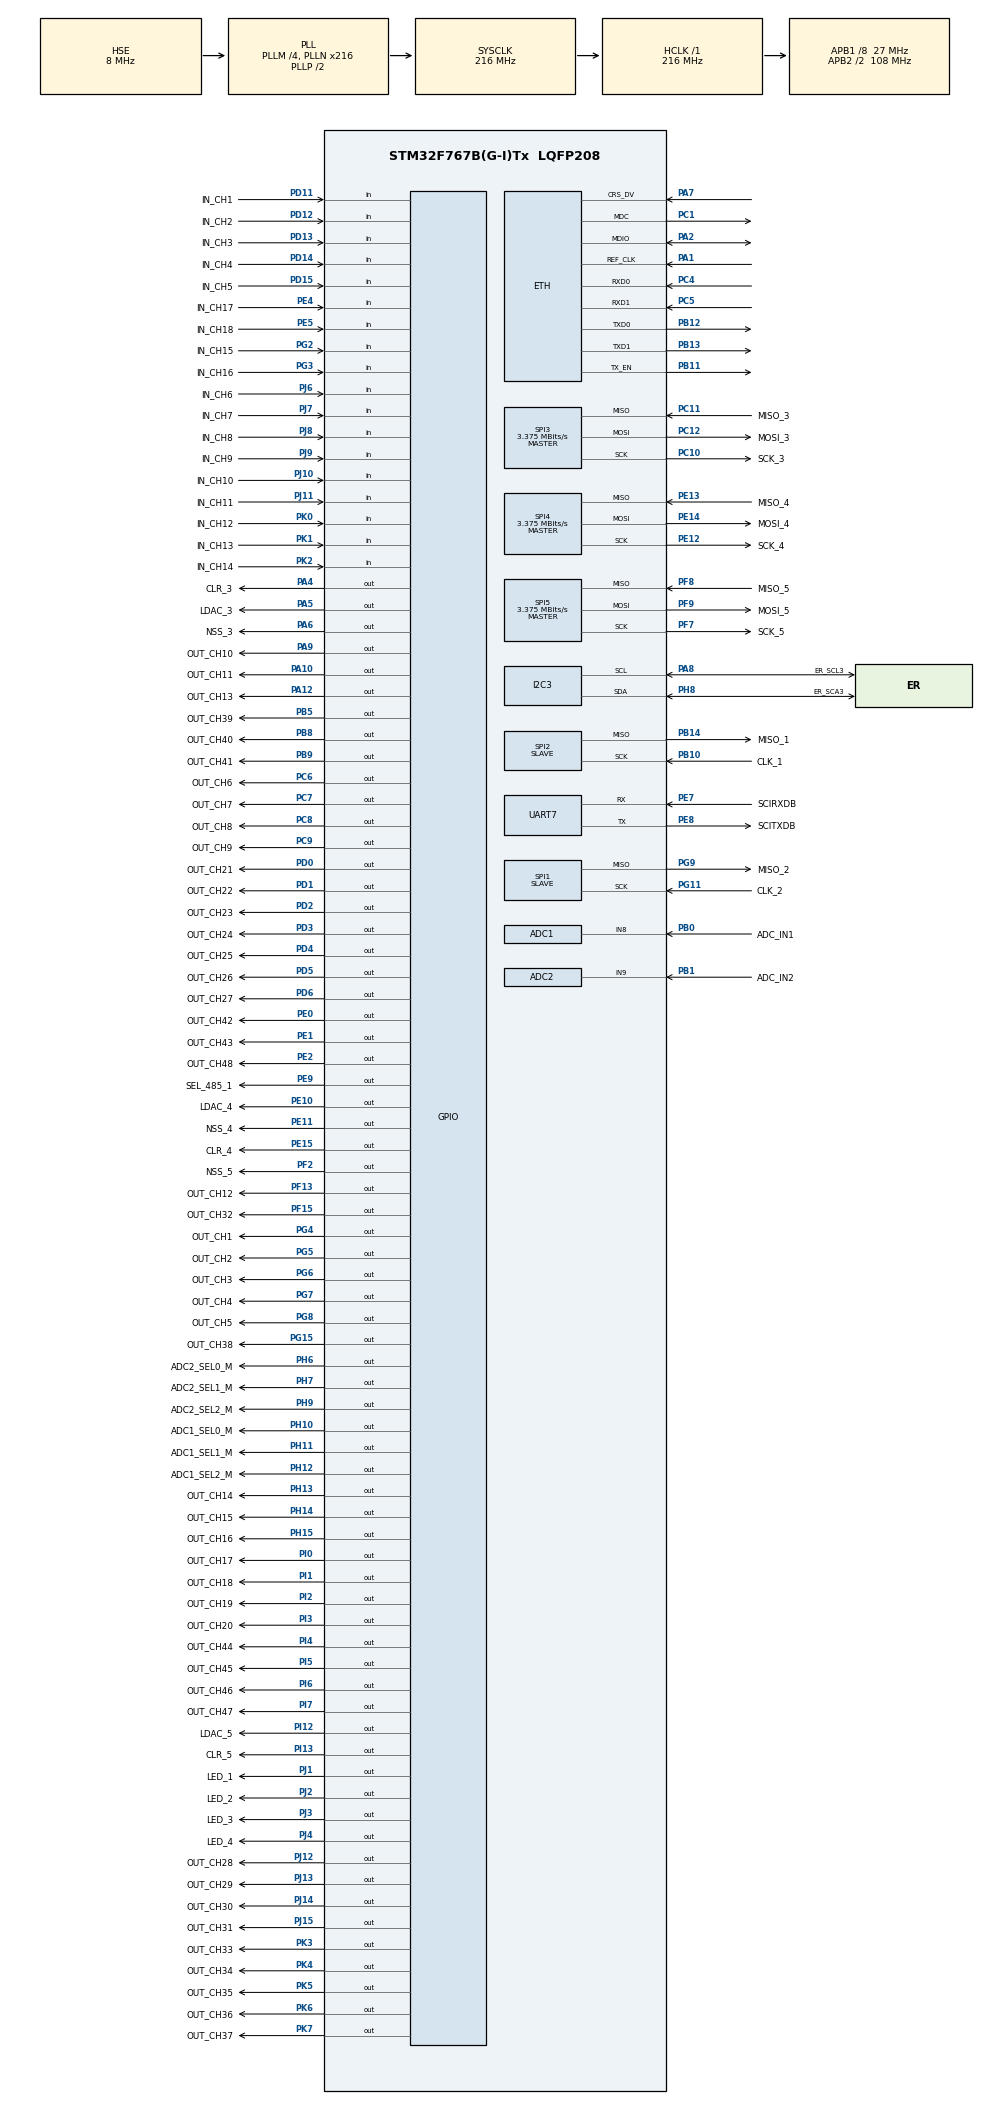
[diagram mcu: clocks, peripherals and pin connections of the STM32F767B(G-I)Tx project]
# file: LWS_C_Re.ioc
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ADC1.Channel-0\#ChannelRegularConversion=ADC_CHANNEL_8
ADC1.ClockPrescaler=ADC_CLOCK_SYNC_PCLK_DIV6
ADC1.EOCSelection=ADC_EOC_SEQ_CONV
ADC1.NbrOfConversionFlag=1
ADC1.Rank-0\#ChannelRegularConversion=1
ADC1.SamplingTime-0\#ChannelRegularConversion=ADC_SAMPLETIME_84CYCLES
ADC1.master=1
ADC2.Channel-0\#ChannelRegularConversion=ADC_CHANNEL_9
ADC2.ClockPrescaler=ADC_CLOCK_SYNC_PCLK_DIV6
ADC2.ContinuousConvMode=DISABLE
ADC2.DMAContinuousRequests=DISABLE
ADC2.EOCSelection=ADC_EOC_SEQ_CONV
ADC2.NbrOfConversion=1
ADC2.NbrOfConversionFlag=1
ADC2.Rank-0\#ChannelRegularConversion=1
ADC2.SamplingTime-0\#ChannelRegularConversion=ADC_SAMPLETIME_84CYCLES
ADC2.ScanConvMode=ADC_SCAN_DISABLE
CORTEX_M7.CPU_DCache=Disabled
CORTEX_M7.CPU_ICache=Disabled
Dma.Request0=UART7_TX
Dma.Request1=SPI1_TX
Dma.Request2=SPI2_TX
Dma.SPI1_TX.1.Direction=DMA_MEMORY_TO_PERIPH
Dma.SPI1_TX.1.FIFOMode=DMA_FIFOMODE_DISABLE
Dma.SPI1_TX.1.Instance=DMA2_Stream3
Dma.SPI1_TX.1.MemDataAlignment=DMA_MDATAALIGN_HALFWORD
Dma.SPI1_TX.1.MemInc=DMA_MINC_ENABLE
Dma.SPI1_TX.1.Mode=DMA_CIRCULAR
Dma.SPI1_TX.1.PeriphDataAlignment=DMA_PDATAALIGN_HALFWORD
Dma.SPI1_TX.1.PeriphInc=DMA_PINC_DISABLE
Dma.SPI1_TX.1.Priority=DMA_PRIORITY_LOW
Dma.SPI2_TX.2.Direction=DMA_MEMORY_TO_PERIPH
Dma.SPI2_TX.2.FIFOMode=DMA_FIFOMODE_DISABLE
Dma.SPI2_TX.2.Instance=DMA1_Stream4
Dma.SPI2_TX.2.MemDataAlignment=DMA_MDATAALIGN_HALFWORD
Dma.SPI2_TX.2.MemInc=DMA_MINC_ENABLE
Dma.SPI2_TX.2.Mode=DMA_CIRCULAR
Dma.SPI2_TX.2.PeriphDataAlignment=DMA_PDATAALIGN_HALFWORD
Dma.SPI2_TX.2.PeriphInc=DMA_PINC_DISABLE
Dma.SPI2_TX.2.Priority=DMA_PRIORITY_LOW
Dma.UART7_TX.0.Direction=DMA_MEMORY_TO_PERIPH
Dma.UART7_TX.0.FIFOMode=DMA_FIFOMODE_DISABLE
Dma.UART7_TX.0.Instance=DMA1_Stream1
Dma.UART7_TX.0.MemDataAlignment=DMA_MDATAALIGN_BYTE
Dma.UART7_TX.0.MemInc=DMA_MINC_ENABLE
Dma.UART7_TX.0.Mode=DMA_NORMAL
Dma.UART7_TX.0.PeriphDataAlignment=DMA_PDATAALIGN_BYTE
Dma.UART7_TX.0.PeriphInc=DMA_PINC_DISABLE
Dma.UART7_TX.0.Priority=DMA_PRIORITY_VERY_HIGH
ETH.MediaInterface=HAL_ETH_RMII_MODE
I2C3.Timing=0x00606A9B
LWIP.BSP.number=1
LWIP.GATEWAY_ADDRESS=192.168.000.001
LWIP.IP_ADDRESS=192.168.000.225
LWIP.LWIP_DHCP=0
LWIP.NETMASK_ADDRESS=255.255.255.000
LWIP.Version=v2.1.2_Cube
LWIP0.BSP.STBoard=false
LWIP0.BSP.api=BSP_COMPONENT_DRIVER
LWIP0.BSP.component=LAN8742
LWIP0.BSP.instance=LAN8742
LWIP0.BSP.name=Driver_PHY
LWIP0.BSP.semaphore=S_LAN8742
LWIP0.BSP.solution=LAN8742
Mcu.Family=STM32F7
Mcu.Name=STM32F767B(G-I)Tx
Mcu.Package=LQFP208
NVIC.DMA1_Stream1_IRQn=true\:0\:0\:false\:false\:true\:false\:true\:true
NVIC.DMA1_Stream4_IRQn=true\:0\:0\:false\:false\:true\:false\:true\:true
NVIC.DMA2_Stream3_IRQn=true\:0\:0\:false\:false\:true\:false\:true\:true
NVIC.ETH_IRQn=true\:0\:0\:false\:false\:true\:true\:true\:true
NVIC.ETH_WKUP_IRQn=true\:0\:0\:false\:false\:true\:true\:true\:true
NVIC.PriorityGroup=NVIC_PRIORITYGROUP_4
NVIC.SPI1_IRQn=true\:0\:0\:false\:false\:true\:true\:true\:true
NVIC.SPI2_IRQn=true\:0\:0\:false\:false\:true\:true\:true\:true
NVIC.TIM2_IRQn=true\:0\:0\:false\:false\:true\:true\:true\:true
NVIC.TIM4_IRQn=true\:0\:0\:false\:false\:true\:true\:true\:true
NVIC.TIM5_IRQn=true\:0\:0\:false\:false\:true\:true\:true\:true
NVIC.TIM6_DAC_IRQn=true\:15\:0\:false\:false\:true\:false\:true\:true
NVIC.TIM7_IRQn=true\:0\:0\:false\:false\:true\:true\:true\:true
NVIC.TimeBase=TIM6_DAC_IRQn
NVIC.TimeBaseIP=TIM6
NVIC.UART7_IRQn=true\:0\:0\:false\:false\:true\:true\:true\:true
PA1.Mode=RMII
PA1.Signal=ETH_REF_CLK
PA10.GPIO_Label=OUT_CH11
PA10.PinState=GPIO_PIN_SET
PA10.Signal=GPIO_Output
PA12.GPIO_Label=OUT_CH13
PA12.PinState=GPIO_PIN_SET
PA12.Signal=GPIO_Output
PA13.Mode=JTAG_5_pins
PA13.Signal=SYS_JTMS-SWDIO
PA14.Mode=JTAG_5_pins
PA14.Signal=SYS_JTCK-SWCLK
PA15.Mode=JTAG_5_pins
PA15.Signal=SYS_JTDI
PA2.Mode=RMII
PA2.Signal=ETH_MDIO
PA4.GPIO_Label=CLR_3
PA4.Signal=GPIO_Output
PA5.GPIO_Label=LDAC_3
PA5.Signal=GPIO_Output
PA6.GPIO_Label=NSS_3
PA6.Signal=GPIO_Output
PA7.Mode=RMII
PA7.Signal=ETH_CRS_DV
PA8.GPIO_Label=ER_SCL3
PA8.Mode=I2C
PA8.Signal=I2C3_SCL
PA9.GPIO_Label=OUT_CH10
PA9.PinState=GPIO_PIN_SET
PA9.Signal=GPIO_Output
PB0.GPIO_Label=ADC_IN1
PB0.Signal=ADCx_IN8
PB1.GPIO_Label=ADC_IN2
PB1.Signal=ADCx_IN9
PB10.GPIO_Label=CLK_1
PB10.Mode=TX_Only_Simplex_Unidirect_Slave
PB10.Signal=SPI2_SCK
PB11.Mode=RMII
PB11.Signal=ETH_TX_EN
PB12.Mode=RMII
PB12.Signal=ETH_TXD0
PB13.Mode=RMII
PB13.Signal=ETH_TXD1
PB14.GPIO_Label=MISO_1
PB14.Mode=TX_Only_Simplex_Unidirect_Slave
PB14.Signal=SPI2_MISO
PB3.Mode=JTAG_5_pins
PB3.Signal=SYS_JTDO-SWO
PB4.Mode=JTAG_5_pins
PB4.Signal=SYS_JTRST
PB5.GPIO_Label=OUT_CH39
PB5.PinState=GPIO_PIN_SET
PB5.Signal=GPIO_Output
PB8.GPIO_Label=OUT_CH40
PB8.PinState=GPIO_PIN_SET
PB8.Signal=GPIO_Output
PB9.GPIO_Label=OUT_CH41
PB9.PinState=GPIO_PIN_SET
PB9.Signal=GPIO_Output
PC1.Mode=RMII
PC1.Signal=ETH_MDC
PC10.GPIO_Label=SCK_3
PC10.Mode=Full_Duplex_Master
PC10.Signal=SPI3_SCK
PC11.GPIO_Label=MISO_3
PC11.Mode=Full_Duplex_Master
PC11.Signal=SPI3_MISO
PC12.GPIO_Label=MOSI_3
PC12.Mode=Full_Duplex_Master
PC12.Signal=SPI3_MOSI
PC14/OSC32_IN.Mode=LSE-External-Oscillator
PC14/OSC32_IN.Signal=RCC_OSC32_IN
PC15/OSC32_OUT.Mode=LSE-External-Oscillator
PC15/OSC32_OUT.Signal=RCC_OSC32_OUT
PC4.Mode=RMII
PC4.Signal=ETH_RXD0
PC5.Mode=RMII
PC5.Signal=ETH_RXD1
PC6.GPIO_Label=OUT_CH6
PC6.PinState=GPIO_PIN_SET
PC6.Signal=GPIO_Output
PC7.GPIO_Label=OUT_CH7
PC7.PinState=GPIO_PIN_SET
PC7.Signal=GPIO_Output
PC8.GPIO_Label=OUT_CH8
PC8.PinState=GPIO_PIN_SET
PC8.Signal=GPIO_Output
PC9.GPIO_Label=OUT_CH9
PC9.PinState=GPIO_PIN_SET
PC9.Signal=GPIO_Output
PD0.GPIO_Label=OUT_CH21
PD0.PinState=GPIO_PIN_SET
PD0.Signal=GPIO_Output
PD1.GPIO_Label=OUT_CH22
PD1.PinState=GPIO_PIN_SET
PD1.Signal=GPIO_Output
PD11.GPIO_Label=IN_CH1
PD11.Signal=GPIO_Input
PD12.GPIO_Label=IN_CH2
PD12.Signal=GPIO_Input
PD13.GPIO_Label=IN_CH3
PD13.Signal=GPIO_Input
PD14.GPIO_Label=IN_CH4
PD14.Signal=GPIO_Input
PD15.GPIO_Label=IN_CH5
PD15.Signal=GPIO_Input
PD2.GPIO_Label=OUT_CH23
PD2.PinState=GPIO_PIN_SET
PD2.Signal=GPIO_Output
PD3.GPIO_Label=OUT_CH24
PD3.PinState=GPIO_PIN_SET
PD3.Signal=GPIO_Output
PD4.GPIO_Label=OUT_CH25
PD4.PinState=GPIO_PIN_SET
PD4.Signal=GPIO_Output
PD5.GPIO_Label=OUT_CH26
PD5.PinState=GPIO_PIN_SET
PD5.Signal=GPIO_Output
PD6.GPIO_Label=OUT_CH27
PD6.PinState=GPIO_PIN_SET
PD6.Signal=GPIO_Output
PE0.GPIO_Label=OUT_CH42
PE0.PinState=GPIO_PIN_SET
PE0.Signal=GPIO_Output
PE1.GPIO_Label=OUT_CH43
PE1.PinState=GPIO_PIN_SET
PE1.Signal=GPIO_Output
PE10.GPIO_Label=LDAC_4
PE10.Signal=GPIO_Output
PE11.GPIO_Label=NSS_4
PE11.Signal=GPIO_Output
PE12.GPIO_Label=SCK_4
PE12.Mode=Full_Duplex_Master
PE12.Signal=SPI4_SCK
PE13.GPIO_Label=MISO_4
PE13.Mode=Full_Duplex_Master
PE13.Signal=SPI4_MISO
PE14.GPIO_Label=MOSI_4
PE14.Mode=Full_Duplex_Master
PE14.Signal=SPI4_MOSI
PE15.GPIO_Label=CLR_4
PE15.Signal=GPIO_Output
PE2.GPIO_Label=OUT_CH48
PE2.PinState=GPIO_PIN_SET
PE2.Signal=GPIO_Output
PE4.GPIO_Label=IN_CH17
PE4.Signal=GPIO_Input
PE5.GPIO_Label=IN_CH18
PE5.Signal=GPIO_Input
PE7.GPIO_Label=SCIRXDB
PE7.Mode=Asynchronous
PE7.Signal=UART7_RX
PE8.GPIO_Label=SCITXDB
PE8.Mode=Asynchronous
PE8.Signal=UART7_TX
PE9.GPIO_Label=SEL_485_1
PE9.Signal=GPIO_Output
PF13.GPIO_Label=OUT_CH12
PF13.PinState=GPIO_PIN_SET
PF13.Signal=GPIO_Output
PF15.GPIO_Label=OUT_CH32
PF15.PinState=GPIO_PIN_SET
PF15.Signal=GPIO_Output
PF2.GPIO_Label=NSS_5
PF2.Signal=GPIO_Output
PF7.GPIO_Label=SCK_5
PF7.Mode=Full_Duplex_Master
PF7.Signal=SPI5_SCK
PF8.GPIO_Label=MISO_5
PF8.Mode=Full_Duplex_Master
PF8.Signal=SPI5_MISO
PF9.GPIO_Label=MOSI_5
PF9.Mode=Full_Duplex_Master
PF9.Signal=SPI5_MOSI
PG11.GPIO_Label=CLK_2
PG11.Mode=TX_Only_Simplex_Unidirect_Slave
PG11.Signal=SPI1_SCK
PG15.GPIO_Label=OUT_CH38
PG15.PinState=GPIO_PIN_SET
PG15.Signal=GPIO_Output
PG2.GPIO_Label=IN_CH15
PG2.Signal=GPIO_Input
PG3.GPIO_Label=IN_CH16
PG3.Signal=GPIO_Input
PG4.GPIO_Label=OUT_CH1
PG4.PinState=GPIO_PIN_SET
PG4.Signal=GPIO_Output
PG5.GPIO_Label=OUT_CH2
PG5.PinState=GPIO_PIN_SET
PG5.Signal=GPIO_Output
PG6.GPIO_Label=OUT_CH3
PG6.PinState=GPIO_PIN_SET
PG6.Signal=GPIO_Output
PG7.GPIO_Label=OUT_CH4
PG7.PinState=GPIO_PIN_SET
PG7.Signal=GPIO_Output
PG8.GPIO_Label=OUT_CH5
PG8.PinState=GPIO_PIN_SET
PG8.Signal=GPIO_Output
PG9.GPIO_Label=MISO_2
PG9.Mode=TX_Only_Simplex_Unidirect_Slave
PG9.Signal=SPI1_MISO
PH0/OSC_IN.Mode=HSE-External-Oscillator
PH0/OSC_IN.Signal=RCC_OSC_IN
PH1/OSC_OUT.Mode=HSE-External-Oscillator
PH1/OSC_OUT.Signal=RCC_OSC_OUT
PH10.GPIO_Label=ADC1_SEL0_M
PH10.Signal=GPIO_Output
PH11.GPIO_Label=ADC1_SEL1_M
PH11.Signal=GPIO_Output
PH12.GPIO_Label=ADC1_SEL2_M
PH12.Signal=GPIO_Output
PH13.GPIO_Label=OUT_CH14
PH13.PinState=GPIO_PIN_SET
PH13.Signal=GPIO_Output
PH14.GPIO_Label=OUT_CH15
PH14.PinState=GPIO_PIN_SET
PH14.Signal=GPIO_Output
PH15.GPIO_Label=OUT_CH16
PH15.PinState=GPIO_PIN_SET
PH15.Signal=GPIO_Output
PH6.GPIO_Label=ADC2_SEL0_M
PH6.Signal=GPIO_Output
PH7.GPIO_Label=ADC2_SEL1_M
PH7.Signal=GPIO_Output
PH8.GPIO_Label=ER_SCA3
PH8.Mode=I2C
PH8.Signal=I2C3_SDA
PH9.GPIO_Label=ADC2_SEL2_M
PH9.Signal=GPIO_Output
PI0.GPIO_Label=OUT_CH17
PI0.PinState=GPIO_PIN_SET
PI0.Signal=GPIO_Output
PI1.GPIO_Label=OUT_CH18
PI1.PinState=GPIO_PIN_SET
PI1.Signal=GPIO_Output
PI12.GPIO_Label=LDAC_5
PI12.Signal=GPIO_Output
PI13.GPIO_Label=CLR_5
PI13.Signal=GPIO_Output
PI2.GPIO_Label=OUT_CH19
PI2.PinState=GPIO_PIN_SET
PI2.Signal=GPIO_Output
PI3.GPIO_Label=OUT_CH20
PI3.PinState=GPIO_PIN_SET
PI3.Signal=GPIO_Output
PI4.GPIO_Label=OUT_CH44
PI4.PinState=GPIO_PIN_SET
PI4.Signal=GPIO_Output
PI5.GPIO_Label=OUT_CH45
PI5.PinState=GPIO_PIN_SET
PI5.Signal=GPIO_Output
PI6.GPIO_Label=OUT_CH46
PI6.PinState=GPIO_PIN_SET
PI6.Signal=GPIO_Output
PI7.GPIO_Label=OUT_CH47
PI7.PinState=GPIO_PIN_SET
PI7.Signal=GPIO_Output
PJ1.GPIO_Label=LED_1
PJ1.Signal=GPIO_Output
PJ10.GPIO_Label=IN_CH10
PJ10.Signal=GPIO_Input
PJ11.GPIO_Label=IN_CH11
PJ11.Signal=GPIO_Input
PJ12.GPIO_Label=OUT_CH28
PJ12.PinState=GPIO_PIN_SET
PJ12.Signal=GPIO_Output
PJ13.GPIO_Label=OUT_CH29
PJ13.PinState=GPIO_PIN_SET
PJ13.Signal=GPIO_Output
PJ14.GPIO_Label=OUT_CH30
PJ14.PinState=GPIO_PIN_SET
PJ14.Signal=GPIO_Output
PJ15.GPIO_Label=OUT_CH31
PJ15.PinState=GPIO_PIN_SET
PJ15.Signal=GPIO_Output
PJ2.GPIO_Label=LED_2
PJ2.Signal=GPIO_Output
PJ3.GPIO_Label=LED_3
PJ3.Signal=GPIO_Output
PJ4.GPIO_Label=LED_4
PJ4.Signal=GPIO_Output
PJ6.GPIO_Label=IN_CH6
PJ6.Signal=GPIO_Input
PJ7.GPIO_Label=IN_CH7
PJ7.Signal=GPIO_Input
PJ8.GPIO_Label=IN_CH8
PJ8.Signal=GPIO_Input
PJ9.GPIO_Label=IN_CH9
PJ9.Signal=GPIO_Input
PK0.GPIO_Label=IN_CH12
PK0.Signal=GPIO_Input
PK1.GPIO_Label=IN_CH13
PK1.Signal=GPIO_Input
PK2.GPIO_Label=IN_CH14
PK2.Signal=GPIO_Input
PK3.GPIO_Label=OUT_CH33
PK3.PinState=GPIO_PIN_SET
PK3.Signal=GPIO_Output
PK4.GPIO_Label=OUT_CH34
PK4.PinState=GPIO_PIN_SET
PK4.Signal=GPIO_Output
PK5.GPIO_Label=OUT_CH35
PK5.PinState=GPIO_PIN_SET
PK5.Signal=GPIO_Output
PK6.GPIO_Label=OUT_CH36
PK6.PinState=GPIO_PIN_SET
PK6.Signal=GPIO_Output
PK7.GPIO_Label=OUT_CH37
PK7.PinState=GPIO_PIN_SET
PK7.Signal=GPIO_Output
ProjectManager.HeapSize=0x2000
ProjectManager.StackSize=0x4000
ProjectManager.TargetToolchain=STM32CubeIDE
RCC.AHBFreq_Value=216000000
RCC.APB1CLKDivider=RCC_HCLK_DIV8
RCC.APB1Freq_Value=27000000
RCC.APB1TimFreq_Value=54000000
RCC.APB2CLKDivider=RCC_HCLK_DIV2
RCC.APB2Freq_Value=108000000
RCC.APB2TimFreq_Value=216000000
RCC.CortexFreq_Value=216000000
RCC.HCLKFreq_Value=216000000
RCC.HSE_VALUE=8000000
RCC.HSI_VALUE=16000000
RCC.PLLM=4
RCC.PLLN=216
RCC.PLLSourceVirtual=RCC_PLLSOURCE_HSE
RCC.SYSCLKFreq_VALUE=216000000
RCC.SYSCLKSource=RCC_SYSCLKSOURCE_PLLCLK
RCC.USBFreq_Value=216000000
RCC.VCOOutputFreq_Value=432000000
SH.ADCx_IN8.0=ADC1_IN8,IN8
SH.ADCx_IN9.0=ADC2_IN9,IN9
SPI1.CLKPhase=SPI_PHASE_1EDGE
SPI1.CLKPolarity=SPI_POLARITY_LOW
SPI1.CRCCalculation=SPI_CRCCALCULATION_DISABLE
SPI1.DataSize=SPI_DATASIZE_16BIT
SPI1.Direction=SPI_DIRECTION_2LINES
SPI1.Mode=SPI_MODE_SLAVE
SPI1.TIMode=SPI_TIMODE_DISABLE
SPI1.VirtualType=VM_SLAVE
SPI2.CLKPhase=SPI_PHASE_1EDGE
SPI2.CLKPolarity=SPI_POLARITY_LOW
SPI2.DataSize=SPI_DATASIZE_16BIT
SPI2.Direction=SPI_DIRECTION_2LINES
SPI2.FirstBit=SPI_FIRSTBIT_MSB
SPI2.Mode=SPI_MODE_SLAVE
SPI2.TIMode=SPI_TIMODE_DISABLE
SPI2.VirtualType=VM_SLAVE
SPI3.BaudRatePrescaler=SPI_BAUDRATEPRESCALER_8
SPI3.CalculateBaudRate=3.375 MBits/s
SPI3.DataSize=SPI_DATASIZE_8BIT
SPI3.Direction=SPI_DIRECTION_2LINES
SPI3.Mode=SPI_MODE_MASTER
SPI3.VirtualType=VM_MASTER
SPI4.BaudRatePrescaler=SPI_BAUDRATEPRESCALER_32
SPI4.CalculateBaudRate=3.375 MBits/s
SPI4.DataSize=SPI_DATASIZE_8BIT
SPI4.Direction=SPI_DIRECTION_2LINES
SPI4.Mode=SPI_MODE_MASTER
SPI4.VirtualType=VM_MASTER
SPI5.BaudRatePrescaler=SPI_BAUDRATEPRESCALER_32
SPI5.CalculateBaudRate=3.375 MBits/s
SPI5.DataSize=SPI_DATASIZE_8BIT
SPI5.Direction=SPI_DIRECTION_2LINES
SPI5.Mode=SPI_MODE_MASTER
SPI5.VirtualType=VM_MASTER
TIM2.Period=3
TIM2.Prescaler=269
TIM4.Period=4999
TIM4.Prescaler=10799
TIM5.Period=4999
TIM5.Prescaler=10799
TIM7.Period=4999
TIM7.Prescaler=10799
UART7.DMADisableonRxErrorParam=UART_ADVFEATURE_DMA_ENABLEONRXERROR
UART7.OneBitSampling=UART_ONE_BIT_SAMPLE_DISABLE
UART7.OverrunDisableParam=UART_ADVFEATURE_OVERRUN_DISABLE
VP_LWIP_VS_Enabled.Mode=Enabled
VP_SYS_VS_tim6.Mode=TIM6
VP_TIM2_VS_ClockSourceINT.Mode=Internal
VP_TIM4_VS_ClockSourceINT.Mode=Internal
VP_TIM5_VS_ClockSourceINT.Mode=Internal
VP_TIM7_VS_ClockSourceINT.Mode=Enable_Timer
board=custom

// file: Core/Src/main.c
/* USER CODE BEGIN Header */
/**
  ******************************************************************************
  * @file           : main.c
  * @brief          : Main program body
  ******************************************************************************
  * @attention
  *
  * Copyright (c) 2023 STMicroelectronics.
  * All rights reserved.
  *
  * This software is licensed under terms that can be found in the LICENSE file
  * in the root directory of this software component.
  * If no LICENSE file comes with this software, it is provided AS-IS.
  *
  ******************************************************************************
  */
/* USER CODE END Header */
#include "main.h"
#include "lwip.h"

/* USER CODE BEGIN Includes */
#include "../Source/Control/Control.h"
#include "../Source/ETH/tcp_echoserver.h"
/* USER CODE END Includes */

ADC_HandleTypeDef hadc1;
ADC_HandleTypeDef hadc2;

I2C_HandleTypeDef hi2c3;

SPI_HandleTypeDef hspi1;
SPI_HandleTypeDef hspi2;
SPI_HandleTypeDef hspi3;
SPI_HandleTypeDef hspi4;
SPI_HandleTypeDef hspi5;
DMA_HandleTypeDef hdma_spi1_tx;
DMA_HandleTypeDef hdma_spi2_tx;

TIM_HandleTypeDef htim2;
TIM_HandleTypeDef htim4;
TIM_HandleTypeDef htim5;
TIM_HandleTypeDef htim7;

UART_HandleTypeDef huart7;
DMA_HandleTypeDef hdma_uart7_tx;

void SystemClock_Config(void);
static void MX_GPIO_Init(void);
static void MX_DMA_Init(void);
static void MX_ADC2_Init(void);
static void MX_I2C3_Init(void);
static void MX_SPI1_Init(void);
static void MX_SPI2_Init(void);
static void MX_TIM2_Init(void);
static void MX_TIM4_Init(void);
static void MX_TIM5_Init(void);
static void MX_TIM7_Init(void);
static void MX_SPI3_Init(void);
static void MX_SPI4_Init(void);
static void MX_SPI5_Init(void);
static void MX_UART7_Init(void);
static void MX_ADC1_Init(void);

int main(void)
{

  /* MCU Configuration--------------------------------------------------------*/

  /* Reset of all peripherals, Initializes the Flash interface and the Systick. */
  HAL_Init();

  /* Configure the system clock */
  SystemClock_Config();

  /* Initialize all configured peripherals */
  MX_GPIO_Init();
  MX_DMA_Init();
  MX_ADC2_Init();
  MX_I2C3_Init();
  MX_SPI1_Init();
  MX_SPI2_Init();
  MX_TIM2_Init();
  MX_TIM4_Init();
  MX_TIM5_Init();
  MX_TIM7_Init();
//  MX_LWIP_Init();
  MX_SPI3_Init();
  MX_SPI4_Init();
  MX_SPI5_Init();
  MX_UART7_Init();
  MX_ADC1_Init();
  /* USER CODE BEGIN 2 */

  FUN_Control_Init();

//  tcp_echoserver_init();
  /* USER CODE END 2 */

  /* Infinite loop */
  /* USER CODE BEGIN WHILE */
  while (1)
  {
//	  MX_LWIP_Process();

	  FUN_Control_Routine();
    /* USER CODE END WHILE */

  }
}

void SystemClock_Config(void)
{
  RCC_OscInitTypeDef RCC_OscInitStruct = {0};
  RCC_ClkInitTypeDef RCC_ClkInitStruct = {0};

  /** Configure LSE Drive Capability
  */
  HAL_PWR_EnableBkUpAccess();

  /** Configure the main internal regulator output voltage
  */
  __HAL_RCC_PWR_CLK_ENABLE();
  __HAL_PWR_VOLTAGESCALING_CONFIG(PWR_REGULATOR_VOLTAGE_SCALE1);

  /** Initializes the RCC Oscillators according to the specified parameters
  * in the RCC_OscInitTypeDef structure.
  */
  RCC_OscInitStruct.OscillatorType = RCC_OSCILLATORTYPE_HSE;
  RCC_OscInitStruct.HSEState = RCC_HSE_ON;
  RCC_OscInitStruct.PLL.PLLState = RCC_PLL_ON;
  RCC_OscInitStruct.PLL.PLLSource = RCC_PLLSOURCE_HSE;
  RCC_OscInitStruct.PLL.PLLM = 4;
  RCC_OscInitStruct.PLL.PLLN = 216;
  RCC_OscInitStruct.PLL.PLLP = RCC_PLLP_DIV2;
  RCC_OscInitStruct.PLL.PLLQ = 2;
  RCC_OscInitStruct.PLL.PLLR = 2;
  if (HAL_RCC_OscConfig(&RCC_OscInitStruct) != HAL_OK)
  {
    Error_Handler();
  }

  /** Activate the Over-Drive mode
  */
  if (HAL_PWREx_EnableOverDrive() != HAL_OK)
  {
    Error_Handler();
  }

  /** Initializes the CPU, AHB and APB buses clocks
  */
  RCC_ClkInitStruct.ClockType = RCC_CLOCKTYPE_HCLK|RCC_CLOCKTYPE_SYSCLK
                              |RCC_CLOCKTYPE_PCLK1|RCC_CLOCKTYPE_PCLK2;
  RCC_ClkInitStruct.SYSCLKSource = RCC_SYSCLKSOURCE_PLLCLK;
  RCC_ClkInitStruct.AHBCLKDivider = RCC_SYSCLK_DIV1;
  RCC_ClkInitStruct.APB1CLKDivider = RCC_HCLK_DIV8;
  RCC_ClkInitStruct.APB2CLKDivider = RCC_HCLK_DIV2;

  if (HAL_RCC_ClockConfig(&RCC_ClkInitStruct, FLASH_LATENCY_7) != HAL_OK)
  {
    Error_Handler();
  }
}

static void MX_ADC1_Init(void)
{

  ADC_ChannelConfTypeDef sConfig = {0};

  /** Configure the global features of the ADC (Clock, Resolution, Data Alignment and number of conversion)
  */
  hadc1.Instance = ADC1;
  hadc1.Init.ClockPrescaler = ADC_CLOCK_SYNC_PCLK_DIV6;
  hadc1.Init.Resolution = ADC_RESOLUTION_12B;
  hadc1.Init.ScanConvMode = ADC_SCAN_DISABLE;
  hadc1.Init.ContinuousConvMode = DISABLE;
  hadc1.Init.DiscontinuousConvMode = DISABLE;
  hadc1.Init.ExternalTrigConvEdge = ADC_EXTERNALTRIGCONVEDGE_NONE;
  hadc1.Init.ExternalTrigConv = ADC_SOFTWARE_START;
  hadc1.Init.DataAlign = ADC_DATAALIGN_RIGHT;
  hadc1.Init.NbrOfConversion = 1;
  hadc1.Init.DMAContinuousRequests = DISABLE;
  hadc1.Init.EOCSelection = ADC_EOC_SEQ_CONV;
  if (HAL_ADC_Init(&hadc1) != HAL_OK)
  {
    Error_Handler();
  }

  /** Configure for the selected ADC regular channel its corresponding rank in the sequencer and its sample time.
  */
  sConfig.Channel = ADC_CHANNEL_8;
  sConfig.Rank = ADC_REGULAR_RANK_1;
  sConfig.SamplingTime = ADC_SAMPLETIME_84CYCLES;
  if (HAL_ADC_ConfigChannel(&hadc1, &sConfig) != HAL_OK)
  {
    Error_Handler();
  }

}

static void MX_ADC2_Init(void)
{

  ADC_ChannelConfTypeDef sConfig = {0};

  /** Configure the global features of the ADC (Clock, Resolution, Data Alignment and number of conversion)
  */
  hadc2.Instance = ADC2;
  hadc2.Init.ClockPrescaler = ADC_CLOCK_SYNC_PCLK_DIV6;
  hadc2.Init.Resolution = ADC_RESOLUTION_12B;
  hadc2.Init.ScanConvMode = ADC_SCAN_DISABLE;
  hadc2.Init.ContinuousConvMode = DISABLE;
  hadc2.Init.DiscontinuousConvMode = DISABLE;
  hadc2.Init.ExternalTrigConvEdge = ADC_EXTERNALTRIGCONVEDGE_NONE;
  hadc2.Init.ExternalTrigConv = ADC_SOFTWARE_START;
  hadc2.Init.DataAlign = ADC_DATAALIGN_RIGHT;
  hadc2.Init.NbrOfConversion = 1;
  hadc2.Init.DMAContinuousRequests = DISABLE;
  hadc2.Init.EOCSelection = ADC_EOC_SEQ_CONV;
  if (HAL_ADC_Init(&hadc2) != HAL_OK)
  {
    Error_Handler();
  }

  /** Configure for the selected ADC regular channel its corresponding rank in the sequencer and its sample time.
  */
  sConfig.Channel = ADC_CHANNEL_9;
  sConfig.Rank = ADC_REGULAR_RANK_1;
  sConfig.SamplingTime = ADC_SAMPLETIME_84CYCLES;
  if (HAL_ADC_ConfigChannel(&hadc2, &sConfig) != HAL_OK)
  {
    Error_Handler();
  }

}

static void MX_I2C3_Init(void)
{

  hi2c3.Instance = I2C3;
  hi2c3.Init.Timing = 0x00606A9B;
  hi2c3.Init.OwnAddress1 = 0;
  hi2c3.Init.AddressingMode = I2C_ADDRESSINGMODE_7BIT;
  hi2c3.Init.DualAddressMode = I2C_DUALADDRESS_DISABLE;
  hi2c3.Init.OwnAddress2 = 0;
  hi2c3.Init.OwnAddress2Masks = I2C_OA2_NOMASK;
  hi2c3.Init.GeneralCallMode = I2C_GENERALCALL_DISABLE;
  hi2c3.Init.NoStretchMode = I2C_NOSTRETCH_DISABLE;
  if (HAL_I2C_Init(&hi2c3) != HAL_OK)
  {
    Error_Handler();
  }

  /** Configure Analogue filter
  */
  if (HAL_I2CEx_ConfigAnalogFilter(&hi2c3, I2C_ANALOGFILTER_ENABLE) != HAL_OK)
  {
    Error_Handler();
  }

  /** Configure Digital filter
  */
  if (HAL_I2CEx_ConfigDigitalFilter(&hi2c3, 0) != HAL_OK)
  {
    Error_Handler();
  }

}

static void MX_SPI1_Init(void)
{

  /* SPI1 parameter configuration*/
  hspi1.Instance = SPI1;
  hspi1.Init.Mode = SPI_MODE_SLAVE;
  hspi1.Init.Direction = SPI_DIRECTION_2LINES;
  hspi1.Init.DataSize = SPI_DATASIZE_16BIT;
  hspi1.Init.CLKPolarity = SPI_POLARITY_LOW;
  hspi1.Init.CLKPhase = SPI_PHASE_1EDGE;
  hspi1.Init.NSS = SPI_NSS_SOFT;
  hspi1.Init.FirstBit = SPI_FIRSTBIT_MSB;
  hspi1.Init.TIMode = SPI_TIMODE_DISABLE;
  hspi1.Init.CRCCalculation = SPI_CRCCALCULATION_DISABLE;
  hspi1.Init.CRCPolynomial = 7;
  hspi1.Init.CRCLength = SPI_CRC_LENGTH_DATASIZE;
  hspi1.Init.NSSPMode = SPI_NSS_PULSE_DISABLE;
  if (HAL_SPI_Init(&hspi1) != HAL_OK)
  {
    Error_Handler();
  }

}

static void MX_SPI2_Init(void)
{

  /* SPI2 parameter configuration*/
  hspi2.Instance = SPI2;
  hspi2.Init.Mode = SPI_MODE_SLAVE;
  hspi2.Init.Direction = SPI_DIRECTION_2LINES;
  hspi2.Init.DataSize = SPI_DATASIZE_16BIT;
  hspi2.Init.CLKPolarity = SPI_POLARITY_LOW;
  hspi2.Init.CLKPhase = SPI_PHASE_1EDGE;
  hspi2.Init.NSS = SPI_NSS_SOFT;
  hspi2.Init.FirstBit = SPI_FIRSTBIT_MSB;
  hspi2.Init.TIMode = SPI_TIMODE_DISABLE;
  hspi2.Init.CRCCalculation = SPI_CRCCALCULATION_DISABLE;
  hspi2.Init.CRCPolynomial = 7;
  hspi2.Init.CRCLength = SPI_CRC_LENGTH_DATASIZE;
  hspi2.Init.NSSPMode = SPI_NSS_PULSE_DISABLE;
  if (HAL_SPI_Init(&hspi2) != HAL_OK)
  {
    Error_Handler();
  }

}

static void MX_SPI3_Init(void)
{

  /* SPI3 parameter configuration*/
  hspi3.Instance = SPI3;
  hspi3.Init.Mode = SPI_MODE_MASTER;
  hspi3.Init.Direction = SPI_DIRECTION_2LINES;
  hspi3.Init.DataSize = SPI_DATASIZE_8BIT;
  hspi3.Init.CLKPolarity = SPI_POLARITY_LOW;
  hspi3.Init.CLKPhase = SPI_PHASE_1EDGE;
  hspi3.Init.NSS = SPI_NSS_SOFT;
  hspi3.Init.BaudRatePrescaler = SPI_BAUDRATEPRESCALER_8;
  hspi3.Init.FirstBit = SPI_FIRSTBIT_MSB;
  hspi3.Init.TIMode = SPI_TIMODE_DISABLE;
  hspi3.Init.CRCCalculation = SPI_CRCCALCULATION_DISABLE;
  hspi3.Init.CRCPolynomial = 7;
  hspi3.Init.CRCLength = SPI_CRC_LENGTH_DATASIZE;
  hspi3.Init.NSSPMode = SPI_NSS_PULSE_ENABLE;
  if (HAL_SPI_Init(&hspi3) != HAL_OK)
  {
    Error_Handler();
  }

}

static void MX_SPI4_Init(void)
{

  /* SPI4 parameter configuration*/
  hspi4.Instance = SPI4;
  hspi4.Init.Mode = SPI_MODE_MASTER;
  hspi4.Init.Direction = SPI_DIRECTION_2LINES;
  hspi4.Init.DataSize = SPI_DATASIZE_8BIT;
  hspi4.Init.CLKPolarity = SPI_POLARITY_LOW;
  hspi4.Init.CLKPhase = SPI_PHASE_1EDGE;
  hspi4.Init.NSS = SPI_NSS_SOFT;
  hspi4.Init.BaudRatePrescaler = SPI_BAUDRATEPRESCALER_32;
  hspi4.Init.FirstBit = SPI_FIRSTBIT_MSB;
  hspi4.Init.TIMode = SPI_TIMODE_DISABLE;
  hspi4.Init.CRCCalculation = SPI_CRCCALCULATION_DISABLE;
  hspi4.Init.CRCPolynomial = 7;
  hspi4.Init.CRCLength = SPI_CRC_LENGTH_DATASIZE;
  hspi4.Init.NSSPMode = SPI_NSS_PULSE_ENABLE;
  if (HAL_SPI_Init(&hspi4) != HAL_OK)
  {
    Error_Handler();
  }

}

static void MX_SPI5_Init(void)
{

  /* SPI5 parameter configuration*/
  hspi5.Instance = SPI5;
  hspi5.Init.Mode = SPI_MODE_MASTER;
  hspi5.Init.Direction = SPI_DIRECTION_2LINES;
  hspi5.Init.DataSize = SPI_DATASIZE_8BIT;
  hspi5.Init.CLKPolarity = SPI_POLARITY_LOW;
  hspi5.Init.CLKPhase = SPI_PHASE_1EDGE;
  hspi5.Init.NSS = SPI_NSS_SOFT;
  hspi5.Init.BaudRatePrescaler = SPI_BAUDRATEPRESCALER_32;
  hspi5.Init.FirstBit = SPI_FIRSTBIT_MSB;
  hspi5.Init.TIMode = SPI_TIMODE_DISABLE;
  hspi5.Init.CRCCalculation = SPI_CRCCALCULATION_DISABLE;
  hspi5.Init.CRCPolynomial = 7;
  hspi5.Init.CRCLength = SPI_CRC_LENGTH_DATASIZE;
  hspi5.Init.NSSPMode = SPI_NSS_PULSE_ENABLE;
  if (HAL_SPI_Init(&hspi5) != HAL_OK)
  {
    Error_Handler();
  }

}

static void MX_TIM2_Init(void)
{

  TIM_ClockConfigTypeDef sClockSourceConfig = {0};
  TIM_MasterConfigTypeDef sMasterConfig = {0};

  htim2.Instance = TIM2;
  htim2.Init.Prescaler = 269;
  htim2.Init.CounterMode = TIM_COUNTERMODE_UP;
  htim2.Init.Period = 3;
  htim2.Init.ClockDivision = TIM_CLOCKDIVISION_DIV1;
  htim2.Init.AutoReloadPreload = TIM_AUTORELOAD_PRELOAD_DISABLE;
  if (HAL_TIM_Base_Init(&htim2) != HAL_OK)
  {
    Error_Handler();
  }
  sClockSourceConfig.ClockSource = TIM_CLOCKSOURCE_INTERNAL;
  if (HAL_TIM_ConfigClockSource(&htim2, &sClockSourceConfig) != HAL_OK)
  {
    Error_Handler();
  }
  sMasterConfig.MasterOutputTrigger = TIM_TRGO_RESET;
  sMasterConfig.MasterSlaveMode = TIM_MASTERSLAVEMODE_DISABLE;
  if (HAL_TIMEx_MasterConfigSynchronization(&htim2, &sMasterConfig) != HAL_OK)
  {
    Error_Handler();
  }

}

static void MX_TIM4_Init(void)
{

  TIM_ClockConfigTypeDef sClockSourceConfig = {0};
  TIM_MasterConfigTypeDef sMasterConfig = {0};

  htim4.Instance = TIM4;
  htim4.Init.Prescaler = 10799;
  htim4.Init.CounterMode = TIM_COUNTERMODE_UP;
  htim4.Init.Period = 4999;
  htim4.Init.ClockDivision = TIM_CLOCKDIVISION_DIV1;
  htim4.Init.AutoReloadPreload = TIM_AUTORELOAD_PRELOAD_DISABLE;
  if (HAL_TIM_Base_Init(&htim4) != HAL_OK)
  {
    Error_Handler();
  }
  sClockSourceConfig.ClockSource = TIM_CLOCKSOURCE_INTERNAL;
  if (HAL_TIM_ConfigClockSource(&htim4, &sClockSourceConfig) != HAL_OK)
  {
    Error_Handler();
  }
  sMasterConfig.MasterOutputTrigger = TIM_TRGO_RESET;
  sMasterConfig.MasterSlaveMode = TIM_MASTERSLAVEMODE_DISABLE;
  if (HAL_TIMEx_MasterConfigSynchronization(&htim4, &sMasterConfig) != HAL_OK)
  {
    Error_Handler();
  }

}

static void MX_TIM5_Init(void)
{

  TIM_ClockConfigTypeDef sClockSourceConfig = {0};
  TIM_MasterConfigTypeDef sMasterConfig = {0};

  htim5.Instance = TIM5;
  htim5.Init.Prescaler = 10799;
  htim5.Init.CounterMode = TIM_COUNTERMODE_UP;
  htim5.Init.Period = 4999;
  htim5.Init.ClockDivision = TIM_CLOCKDIVISION_DIV1;
  htim5.Init.AutoReloadPreload = TIM_AUTORELOAD_PRELOAD_DISABLE;
  if (HAL_TIM_Base_Init(&htim5) != HAL_OK)
  {
    Error_Handler();
  }
  sClockSourceConfig.ClockSource = TIM_CLOCKSOURCE_INTERNAL;
  if (HAL_TIM_ConfigClockSource(&htim5, &sClockSourceConfig) != HAL_OK)
  {
    Error_Handler();
  }
  sMasterConfig.MasterOutputTrigger = TIM_TRGO_RESET;
  sMasterConfig.MasterSlaveMode = TIM_MASTERSLAVEMODE_DISABLE;
  if (HAL_TIMEx_MasterConfigSynchronization(&htim5, &sMasterConfig) != HAL_OK)
  {
    Error_Handler();
  }

}

static void MX_TIM7_Init(void)
{

  TIM_MasterConfigTypeDef sMasterConfig = {0};

  htim7.Instance = TIM7;
  htim7.Init.Prescaler = 10799;
  htim7.Init.CounterMode = TIM_COUNTERMODE_UP;
  htim7.Init.Period = 4999;
  htim7.Init.AutoReloadPreload = TIM_AUTORELOAD_PRELOAD_DISABLE;
  if (HAL_TIM_Base_Init(&htim7) != HAL_OK)
  {
    Error_Handler();
  }
  sMasterConfig.MasterOutputTrigger = TIM_TRGO_RESET;
  sMasterConfig.MasterSlaveMode = TIM_MASTERSLAVEMODE_DISABLE;
  if (HAL_TIMEx_MasterConfigSynchronization(&htim7, &sMasterConfig) != HAL_OK)
  {
    Error_Handler();
  }

}

static void MX_UART7_Init(void)
{

  huart7.Instance = UART7;
  huart7.Init.BaudRate = 115200;
  huart7.Init.WordLength = UART_WORDLENGTH_8B;
  huart7.Init.StopBits = UART_STOPBITS_1;
  huart7.Init.Parity = UART_PARITY_NONE;
  huart7.Init.Mode = UART_MODE_TX_RX;
  huart7.Init.HwFlowCtl = UART_HWCONTROL_NONE;
  huart7.Init.OverSampling = UART_OVERSAMPLING_16;
  huart7.Init.OneBitSampling = UART_ONE_BIT_SAMPLE_DISABLE;
  huart7.AdvancedInit.AdvFeatureInit = UART_ADVFEATURE_RXOVERRUNDISABLE_INIT;
  huart7.AdvancedInit.OverrunDisable = UART_ADVFEATURE_OVERRUN_DISABLE;
  if (HAL_UART_Init(&huart7) != HAL_OK)
  {
    Error_Handler();
  }

}

static void MX_DMA_Init(void)
{

  /* DMA controller clock enable */
  __HAL_RCC_DMA1_CLK_ENABLE();
  __HAL_RCC_DMA2_CLK_ENABLE();

  /* DMA interrupt init */
  /* DMA1_Stream1_IRQn interrupt configuration */
  HAL_NVIC_SetPriority(DMA1_Stream1_IRQn, 0, 0);
  HAL_NVIC_EnableIRQ(DMA1_Stream1_IRQn);
  /* DMA1_Stream4_IRQn interrupt configuration */
  HAL_NVIC_SetPriority(DMA1_Stream4_IRQn, 0, 0);
  HAL_NVIC_EnableIRQ(DMA1_Stream4_IRQn);
  /* DMA2_Stream3_IRQn interrupt configuration */
  HAL_NVIC_SetPriority(DMA2_Stream3_IRQn, 0, 0);
  HAL_NVIC_EnableIRQ(DMA2_Stream3_IRQn);

}

static void MX_GPIO_Init(void)
{
  GPIO_InitTypeDef GPIO_InitStruct = {0};

  /* GPIO Ports Clock Enable */
  __HAL_RCC_GPIOE_CLK_ENABLE();
  __HAL_RCC_GPIOC_CLK_ENABLE();
  __HAL_RCC_GPIOF_CLK_ENABLE();
  __HAL_RCC_GPIOI_CLK_ENABLE();
  __HAL_RCC_GPIOH_CLK_ENABLE();
  __HAL_RCC_GPIOA_CLK_ENABLE();
  __HAL_RCC_GPIOB_CLK_ENABLE();
  __HAL_RCC_GPIOJ_CLK_ENABLE();
  __HAL_RCC_GPIOD_CLK_ENABLE();
  __HAL_RCC_GPIOK_CLK_ENABLE();
  __HAL_RCC_GPIOG_CLK_ENABLE();

  /*Configure GPIO pin Output Level */
  HAL_GPIO_WritePin(GPIOE, OUT_CH48_Pin|OUT_CH42_Pin|OUT_CH43_Pin, GPIO_PIN_SET);

  /*Configure GPIO pin Output Level */
  HAL_GPIO_WritePin(NSS_5_GPIO_Port, NSS_5_Pin, GPIO_PIN_RESET);

  /*Configure GPIO pin Output Level */
  HAL_GPIO_WritePin(GPIOI, LDAC_5_Pin|CLR_5_Pin, GPIO_PIN_RESET);

  /*Configure GPIO pin Output Level */
  HAL_GPIO_WritePin(GPIOA, CLR_3_Pin|LDAC_3_Pin|NSS_3_Pin, GPIO_PIN_RESET);

  /*Configure GPIO pin Output Level */
  HAL_GPIO_WritePin(GPIOJ, LED_1_Pin|LED_2_Pin|LED_3_Pin|LED_4_Pin, GPIO_PIN_RESET);

  /*Configure GPIO pin Output Level */
  HAL_GPIO_WritePin(GPIOF, OUT_CH12_Pin|OUT_CH32_Pin, GPIO_PIN_SET);

  /*Configure GPIO pin Output Level */
  HAL_GPIO_WritePin(GPIOE, SEL_485_1_Pin|LDAC_4_Pin|NSS_4_Pin|CLR_4_Pin, GPIO_PIN_RESET);

  /*Configure GPIO pin Output Level */
  HAL_GPIO_WritePin(GPIOH, ADC2_SEL0_M_Pin|ADC2_SEL1_M_Pin|ADC2_SEL2_M_Pin|ADC1_SEL0_M_Pin
                          |ADC1_SEL1_M_Pin|ADC1_SEL2_M_Pin, GPIO_PIN_RESET);

  /*Configure GPIO pin Output Level */
  HAL_GPIO_WritePin(GPIOG, OUT_CH1_Pin|OUT_CH2_Pin|OUT_CH3_Pin|OUT_CH4_Pin
                          |OUT_CH5_Pin|OUT_CH38_Pin, GPIO_PIN_SET);

  /*Configure GPIO pin Output Level */
  HAL_GPIO_WritePin(GPIOC, OUT_CH6_Pin|OUT_CH7_Pin|OUT_CH8_Pin|OUT_CH9_Pin, GPIO_PIN_SET);

  /*Configure GPIO pin Output Level */
  HAL_GPIO_WritePin(GPIOA, OUT_CH10_Pin|OUT_CH11_Pin|OUT_CH13_Pin, GPIO_PIN_SET);

  /*Configure GPIO pin Output Level */
  HAL_GPIO_WritePin(GPIOH, OUT_CH14_Pin|OUT_CH15_Pin|OUT_CH16_Pin, GPIO_PIN_SET);

  /*Configure GPIO pin Output Level */
  HAL_GPIO_WritePin(GPIOI, OUT_CH17_Pin|OUT_CH18_Pin|OUT_CH19_Pin|OUT_CH20_Pin
                          |OUT_CH44_Pin|OUT_CH45_Pin|OUT_CH46_Pin|OUT_CH47_Pin, GPIO_PIN_SET);

  /*Configure GPIO pin Output Level */
  HAL_GPIO_WritePin(GPIOD, OUT_CH21_Pin|OUT_CH22_Pin|OUT_CH23_Pin|OUT_CH24_Pin
                          |OUT_CH25_Pin|OUT_CH26_Pin|OUT_CH27_Pin, GPIO_PIN_SET);

  /*Configure GPIO pin Output Level */
  HAL_GPIO_WritePin(GPIOJ, OUT_CH28_Pin|OUT_CH29_Pin|OUT_CH30_Pin|OUT_CH31_Pin, GPIO_PIN_SET);

  /*Configure GPIO pin Output Level */
  HAL_GPIO_WritePin(GPIOK, OUT_CH33_Pin|OUT_CH34_Pin|OUT_CH35_Pin|OUT_CH36_Pin
                          |OUT_CH37_Pin, GPIO_PIN_SET);

  /*Configure GPIO pin Output Level */
  HAL_GPIO_WritePin(GPIOB, OUT_CH39_Pin|OUT_CH40_Pin|OUT_CH41_Pin, GPIO_PIN_SET);

  /*Configure GPIO pins : OUT_CH48_Pin SEL_485_1_Pin LDAC_4_Pin NSS_4_Pin
                           CLR_4_Pin OUT_CH42_Pin OUT_CH43_Pin */
  GPIO_InitStruct.Pin = OUT_CH48_Pin|SEL_485_1_Pin|LDAC_4_Pin|NSS_4_Pin
                          |CLR_4_Pin|OUT_CH42_Pin|OUT_CH43_Pin;
  GPIO_InitStruct.Mode = GPIO_MODE_OUTPUT_PP;
  GPIO_InitStruct.Pull = GPIO_NOPULL;
  GPIO_InitStruct.Speed = GPIO_SPEED_FREQ_LOW;
  HAL_GPIO_Init(GPIOE, &GPIO_InitStruct);

  /*Configure GPIO pins : IN_CH17_Pin IN_CH18_Pin */
  GPIO_InitStruct.Pin = IN_CH17_Pin|IN_CH18_Pin;
  GPIO_InitStruct.Mode = GPIO_MODE_INPUT;
  GPIO_InitStruct.Pull = GPIO_NOPULL;
  HAL_GPIO_Init(GPIOE, &GPIO_InitStruct);

  /*Configure GPIO pins : NSS_5_Pin OUT_CH12_Pin OUT_CH32_Pin */
  GPIO_InitStruct.Pin = NSS_5_Pin|OUT_CH12_Pin|OUT_CH32_Pin;
  GPIO_InitStruct.Mode = GPIO_MODE_OUTPUT_PP;
  GPIO_InitStruct.Pull = GPIO_NOPULL;
  GPIO_InitStruct.Speed = GPIO_SPEED_FREQ_LOW;
  HAL_GPIO_Init(GPIOF, &GPIO_InitStruct);

  /*Configure GPIO pins : LDAC_5_Pin CLR_5_Pin OUT_CH17_Pin OUT_CH18_Pin
                           OUT_CH19_Pin OUT_CH20_Pin OUT_CH44_Pin OUT_CH45_Pin
                           OUT_CH46_Pin OUT_CH47_Pin */
  GPIO_InitStruct.Pin = LDAC_5_Pin|CLR_5_Pin|OUT_CH17_Pin|OUT_CH18_Pin
                          |OUT_CH19_Pin|OUT_CH20_Pin|OUT_CH44_Pin|OUT_CH45_Pin
                          |OUT_CH46_Pin|OUT_CH47_Pin;
  GPIO_InitStruct.Mode = GPIO_MODE_OUTPUT_PP;
  GPIO_InitStruct.Pull = GPIO_NOPULL;
  GPIO_InitStruct.Speed = GPIO_SPEED_FREQ_LOW;
  HAL_GPIO_Init(GPIOI, &GPIO_InitStruct);

  /*Configure GPIO pins : CLR_3_Pin LDAC_3_Pin NSS_3_Pin OUT_CH10_Pin
                           OUT_CH11_Pin OUT_CH13_Pin */
  GPIO_InitStruct.Pin = CLR_3_Pin|LDAC_3_Pin|NSS_3_Pin|OUT_CH10_Pin
                          |OUT_CH11_Pin|OUT_CH13_Pin;
  GPIO_InitStruct.Mode = GPIO_MODE_OUTPUT_PP;
  GPIO_InitStruct.Pull = GPIO_NOPULL;
  GPIO_InitStruct.Speed = GPIO_SPEED_FREQ_LOW;
  HAL_GPIO_Init(GPIOA, &GPIO_InitStruct);

  /*Configure GPIO pins : LED_1_Pin LED_2_Pin LED_3_Pin LED_4_Pin
                           OUT_CH28_Pin OUT_CH29_Pin OUT_CH30_Pin OUT_CH31_Pin */
  GPIO_InitStruct.Pin = LED_1_Pin|LED_2_Pin|LED_3_Pin|LED_4_Pin
                          |OUT_CH28_Pin|OUT_CH29_Pin|OUT_CH30_Pin|OUT_CH31_Pin;
  GPIO_InitStruct.Mode = GPIO_MODE_OUTPUT_PP;
  GPIO_InitStruct.Pull = GPIO_NOPULL;
  GPIO_InitStruct.Speed = GPIO_SPEED_FREQ_LOW;
  HAL_GPIO_Init(GPIOJ, &GPIO_InitStruct);

  /*Configure GPIO pins : ADC2_SEL0_M_Pin ADC2_SEL1_M_Pin ADC2_SEL2_M_Pin ADC1_SEL0_M_Pin
                           ADC1_SEL1_M_Pin ADC1_SEL2_M_Pin OUT_CH14_Pin OUT_CH15_Pin
                           OUT_CH16_Pin */
  GPIO_InitStruct.Pin = ADC2_SEL0_M_Pin|ADC2_SEL1_M_Pin|ADC2_SEL2_M_Pin|ADC1_SEL0_M_Pin
                          |ADC1_SEL1_M_Pin|ADC1_SEL2_M_Pin|OUT_CH14_Pin|OUT_CH15_Pin
                          |OUT_CH16_Pin;
  GPIO_InitStruct.Mode = GPIO_MODE_OUTPUT_PP;
  GPIO_InitStruct.Pull = GPIO_NOPULL;
  GPIO_InitStruct.Speed = GPIO_SPEED_FREQ_LOW;
  HAL_GPIO_Init(GPIOH, &GPIO_InitStruct);

  /*Configure GPIO pins : IN_CH1_Pin IN_CH2_Pin IN_CH3_Pin IN_CH4_Pin
                           IN_CH5_Pin */
  GPIO_InitStruct.Pin = IN_CH1_Pin|IN_CH2_Pin|IN_CH3_Pin|IN_CH4_Pin
                          |IN_CH5_Pin;
  GPIO_InitStruct.Mode = GPIO_MODE_INPUT;
  GPIO_InitStruct.Pull = GPIO_NOPULL;
  HAL_GPIO_Init(GPIOD, &GPIO_InitStruct);

  /*Configure GPIO pins : IN_CH6_Pin IN_CH7_Pin IN_CH8_Pin IN_CH9_Pin
                           IN_CH10_Pin IN_CH11_Pin */
  GPIO_InitStruct.Pin = IN_CH6_Pin|IN_CH7_Pin|IN_CH8_Pin|IN_CH9_Pin
                          |IN_CH10_Pin|IN_CH11_Pin;
  GPIO_InitStruct.Mode = GPIO_MODE_INPUT;
  GPIO_InitStruct.Pull = GPIO_NOPULL;
  HAL_GPIO_Init(GPIOJ, &GPIO_InitStruct);

  /*Configure GPIO pins : IN_CH12_Pin IN_CH13_Pin IN_CH14_Pin */
  GPIO_InitStruct.Pin = IN_CH12_Pin|IN_CH13_Pin|IN_CH14_Pin;
  GPIO_InitStruct.Mode = GPIO_MODE_INPUT;
  GPIO_InitStruct.Pull = GPIO_NOPULL;
  HAL_GPIO_Init(GPIOK, &GPIO_InitStruct);

  /*Configure GPIO pins : IN_CH15_Pin IN_CH16_Pin */
  GPIO_InitStruct.Pin = IN_CH15_Pin|IN_CH16_Pin;
  GPIO_InitStruct.Mode = GPIO_MODE_INPUT;
  GPIO_InitStruct.Pull = GPIO_NOPULL;
  HAL_GPIO_Init(GPIOG, &GPIO_InitStruct);

  /*Configure GPIO pins : OUT_CH1_Pin OUT_CH2_Pin OUT_CH3_Pin OUT_CH4_Pin
                           OUT_CH5_Pin OUT_CH38_Pin */
  GPIO_InitStruct.Pin = OUT_CH1_Pin|OUT_CH2_Pin|OUT_CH3_Pin|OUT_CH4_Pin
                          |OUT_CH5_Pin|OUT_CH38_Pin;
  GPIO_InitStruct.Mode = GPIO_MODE_OUTPUT_PP;
  GPIO_InitStruct.Pull = GPIO_NOPULL;
  GPIO_InitStruct.Speed = GPIO_SPEED_FREQ_LOW;
  HAL_GPIO_Init(GPIOG, &GPIO_InitStruct);

  /*Configure GPIO pins : OUT_CH6_Pin OUT_CH7_Pin OUT_CH8_Pin OUT_CH9_Pin */
  GPIO_InitStruct.Pin = OUT_CH6_Pin|OUT_CH7_Pin|OUT_CH8_Pin|OUT_CH9_Pin;
  GPIO_InitStruct.Mode = GPIO_MODE_OUTPUT_PP;
  GPIO_InitStruct.Pull = GPIO_NOPULL;
  GPIO_InitStruct.Speed = GPIO_SPEED_FREQ_LOW;
  HAL_GPIO_Init(GPIOC, &GPIO_InitStruct);

  /*Configure GPIO pins : OUT_CH21_Pin OUT_CH22_Pin OUT_CH23_Pin OUT_CH24_Pin
                           OUT_CH25_Pin OUT_CH26_Pin OUT_CH27_Pin */
  GPIO_InitStruct.Pin = OUT_CH21_Pin|OUT_CH22_Pin|OUT_CH23_Pin|OUT_CH24_Pin
                          |OUT_CH25_Pin|OUT_CH26_Pin|OUT_CH27_Pin;
  GPIO_InitStruct.Mode = GPIO_MODE_OUTPUT_PP;
  GPIO_InitStruct.Pull = GPIO_NOPULL;
  GPIO_InitStruct.Speed = GPIO_SPEED_FREQ_LOW;
  HAL_GPIO_Init(GPIOD, &GPIO_InitStruct);

  /*Configure GPIO pins : OUT_CH33_Pin OUT_CH34_Pin OUT_CH35_Pin OUT_CH36_Pin
                           OUT_CH37_Pin */
  GPIO_InitStruct.Pin = OUT_CH33_Pin|OUT_CH34_Pin|OUT_CH35_Pin|OUT_CH36_Pin
                          |OUT_CH37_Pin;
  GPIO_InitStruct.Mode = GPIO_MODE_OUTPUT_PP;
  GPIO_InitStruct.Pull = GPIO_NOPULL;
  GPIO_InitStruct.Speed = GPIO_SPEED_FREQ_LOW;
  HAL_GPIO_Init(GPIOK, &GPIO_InitStruct);

  /*Configure GPIO pins : OUT_CH39_Pin OUT_CH40_Pin OUT_CH41_Pin */
  GPIO_InitStruct.Pin = OUT_CH39_Pin|OUT_CH40_Pin|OUT_CH41_Pin;
  GPIO_InitStruct.Mode = GPIO_MODE_OUTPUT_PP;
  GPIO_InitStruct.Pull = GPIO_NOPULL;
  GPIO_InitStruct.Speed = GPIO_SPEED_FREQ_LOW;
  HAL_GPIO_Init(GPIOB, &GPIO_InitStruct);

}

void Error_Handler(void)
{
  __disable_irq();
  while (1)
  {
  }
}
